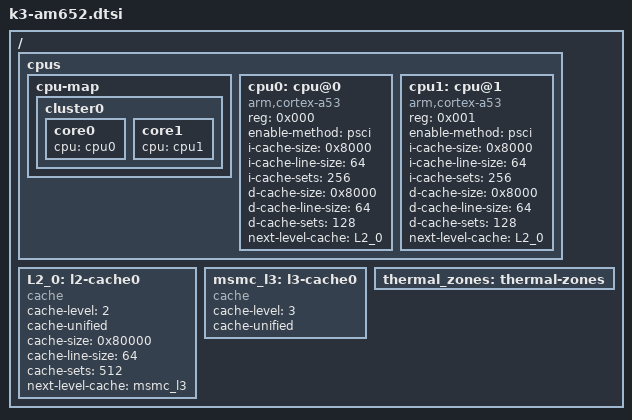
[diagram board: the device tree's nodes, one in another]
// SPDX-License-Identifier: GPL-2.0-only OR MIT
/*
 * Device Tree Source for AM65 SoC family in Dual core configuration
 *
 * Copyright (C) 2023-2024 Texas Instruments Incorporated - https://www.ti.com/
 */

#include "k3-am65.dtsi"

/ {
	cpus {
		#address-cells = <1>;
		#size-cells = <0>;
		cpu-map {
			cluster0: cluster0 {
				core0 {
					cpu = <&cpu0>;
				};

				core1 {
					cpu = <&cpu1>;
				};
			};
		};

		cpu0: cpu@0 {
			compatible = "arm,cortex-a53";
			reg = <0x000>;
			device_type = "cpu";
			enable-method = "psci";
			i-cache-size = <0x8000>;
			i-cache-line-size = <64>;
			i-cache-sets = <256>;
			d-cache-size = <0x8000>;
			d-cache-line-size = <64>;
			d-cache-sets = <128>;
			next-level-cache = <&L2_0>;
		};

		cpu1: cpu@1 {
			compatible = "arm,cortex-a53";
			reg = <0x001>;
			device_type = "cpu";
			enable-method = "psci";
			i-cache-size = <0x8000>;
			i-cache-line-size = <64>;
			i-cache-sets = <256>;
			d-cache-size = <0x8000>;
			d-cache-line-size = <64>;
			d-cache-sets = <128>;
			next-level-cache = <&L2_0>;
		};
	};

	L2_0: l2-cache0 {
		compatible = "cache";
		cache-level = <2>;
		cache-unified;
		cache-size = <0x80000>;
		cache-line-size = <64>;
		cache-sets = <512>;
		next-level-cache = <&msmc_l3>;
	};

	msmc_l3: l3-cache0 {
		compatible = "cache";
		cache-level = <3>;
		cache-unified;
	};

	thermal_zones: thermal-zones {
		#include "k3-am654-industrial-thermal.dtsi"
	};
};
